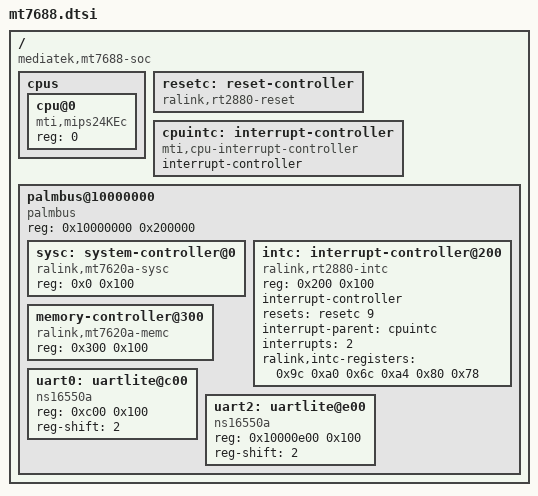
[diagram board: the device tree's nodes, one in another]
/ {
	compatible = "mediatek,mt7688-soc";

	#address-cells = <1>;
	#size-cells = <1>;

	cpus {
		#address-cells = <1>;
		#size-cells = <0>;

		cpu@0 {
			compatible = "mti,mips24KEc";
			device_type = "cpu";
			reg = <0>;
		};
	};

	resetc: reset-controller {
		compatible = "ralink,rt2880-reset";
		#reset-cells = <1>;
	};

	cpuintc: interrupt-controller {
		#address-cells = <0>;
		#interrupt-cells = <1>;
		interrupt-controller;
		compatible = "mti,cpu-interrupt-controller";
	};

	palmbus@10000000 {
		compatible = "palmbus";
		reg = <0x10000000 0x200000>;
		ranges = <0x0 0x10000000 0x1FFFFF>;

		#address-cells = <1>;
		#size-cells = <1>;

		sysc: system-controller@0 {
			compatible = "ralink,mt7620a-sysc", "syscon";
			reg = <0x0 0x100>;
		};

		intc: interrupt-controller@200 {
			compatible = "ralink,rt2880-intc";
			reg = <0x200 0x100>;

			interrupt-controller;
			#interrupt-cells = <1>;

			resets = <&resetc 9>;
			reset-names = "intc";

			interrupt-parent = <&cpuintc>;
			interrupts = <2>;

			ralink,intc-registers = <0x9c 0xa0
						 0x6c 0xa4
						 0x80 0x78>;
		};

		memory-controller@300 {
			compatible = "ralink,mt7620a-memc";
			reg = <0x300 0x100>;
		};

		uart0: uartlite@c00 {
			compatible = "ns16550a";
			reg = <0xc00 0x100>;

			reg-shift = <2>;
		};

		uart2: uartlite@e00 {
			compatible = "ns16550a";
			reg = <0x10000e00 0x100>;

			reg-shift = <2>;
		};

	};
};
